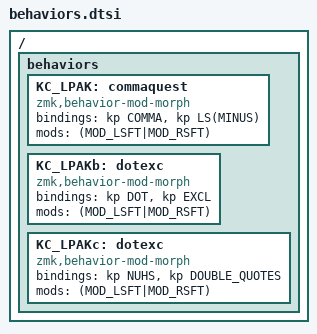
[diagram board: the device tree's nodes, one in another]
#define KEYS_L 0 1 2 3 4 5 12 13 14 15 16 17 24 25 26 27 28 29 36 37 38 19 20 21 22  // Left-hand keys.
#define KEYS_R 6 7 8 9 10 11 18 19 20 21 22 23 30 31 32 33 34 35 39 40 16 15 14 13  // Right-hand keys.
#define THUMBS 36 37 38 39 40  // Thumb keys.

/ {
    behaviors {
        KC_LPAK: commaquest {
            compatible = "zmk,behavior-mod-morph";
            #binding-cells = <0>;
            bindings = <&kp COMMA>, <&kp LS(MINUS)>;
            mods = <(MOD_LSFT|MOD_RSFT)>;
        };

        KC_LPAKb: dotexc {
            compatible = "zmk,behavior-mod-morph";
            #binding-cells = <0>;
            bindings = <&kp DOT>, <&kp EXCL>;
            mods = <(MOD_LSFT|MOD_RSFT)>;
        };

        KC_LPAKc: dotexc {
            compatible = "zmk,behavior-mod-morph";
            #binding-cells = <0>;
            bindings = <&kp NUHS>, <&kp DOUBLE_QUOTES>;
            mods = <(MOD_LSFT|MOD_RSFT)>;
        };
    };
};
